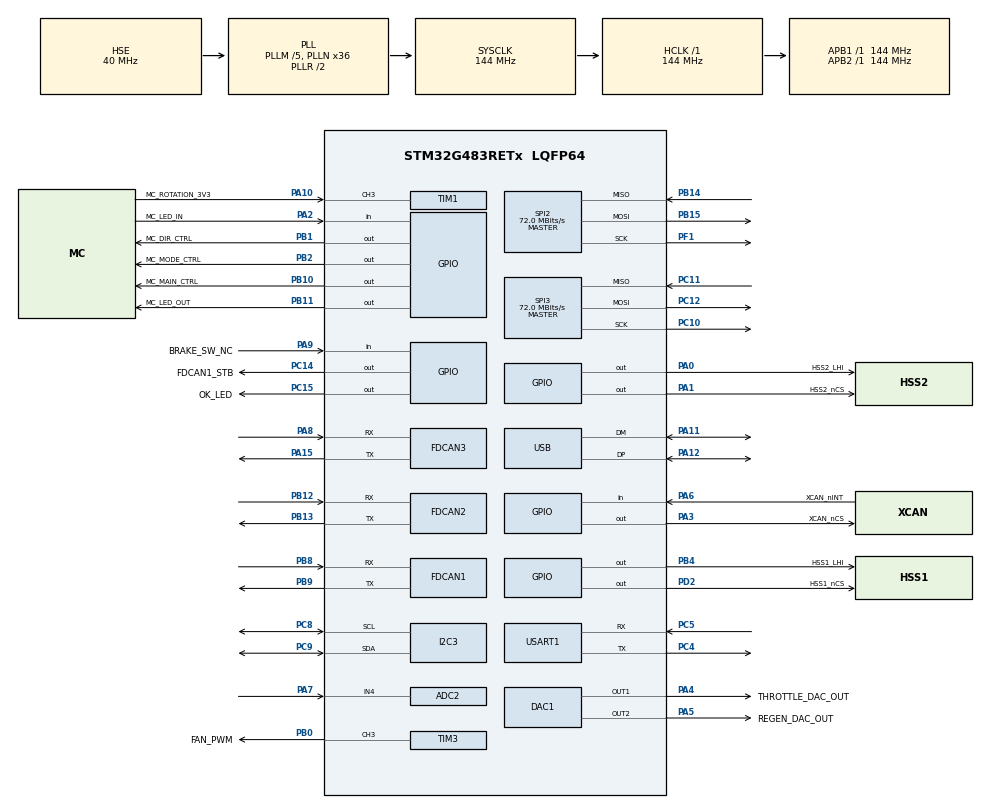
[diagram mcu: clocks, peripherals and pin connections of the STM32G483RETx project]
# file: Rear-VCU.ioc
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ADC2.Channel-0\#ChannelRegularConversion=ADC_CHANNEL_4
ADC2.NbrOfConversionFlag=1
ADC2.OffsetNumber-0\#ChannelRegularConversion=ADC_OFFSET_NONE
ADC2.Rank-0\#ChannelRegularConversion=1
ADC2.SamplingTime-0\#ChannelRegularConversion=ADC_SAMPLETIME_2CYCLES_5
DAC1.DAC_Channel-DAC_OUT2=DAC_CHANNEL_2
FDCAN1.CalculateBaudRateNominal=2999999
FDCAN1.CalculateTimeBitNominal=333
FDCAN1.CalculateTimeQuantumNominal=111.11111111111111
FDCAN2.CalculateBaudRateNominal=2999999
FDCAN2.CalculateTimeBitNominal=333
FDCAN2.CalculateTimeQuantumNominal=111.11111111111111
FDCAN3.CalculateBaudRateNominal=2999999
FDCAN3.CalculateTimeBitNominal=333
FDCAN3.CalculateTimeQuantumNominal=111.11111111111111
FREERTOS.Tasks01=defaultTask,24,128,StartDefaultTask,Default,NULL,Dynamic,NULL,NULL
I2C3.Timing=0x60715075
Mcu.Family=STM32G4
Mcu.Name=STM32G483RETx
Mcu.Package=LQFP64
NVIC.PriorityGroup=NVIC_PRIORITYGROUP_4
NVIC.USB_LP_IRQn=true\:5\:0\:false\:false\:true\:true\:false\:true\:true
PA0.GPIO_Label=HSS2_LHI
PA0.Signal=GPIO_Output
PA1.GPIO_Label=HSS2_nCS
PA1.Signal=GPIO_Output
PA10.GPIO_Label=MC_ROTATION_3V3
PA10.Signal=S_TIM1_CH3
PA11.Mode=Device
PA11.Signal=USB_DM
PA12.Mode=Device
PA12.Signal=USB_DP
PA13.Mode=Trace_Asynchronous_SW
PA13.Signal=SYS_JTMS-SWDIO
PA14.Mode=Trace_Asynchronous_SW
PA14.Signal=SYS_JTCK-SWCLK
PA15.Mode=FDCAN_Activate
PA15.Signal=FDCAN3_TX
PA2.GPIO_Label=MC_LED_IN
PA2.Signal=GPIO_Input
PA3.GPIO_Label=XCAN_nCS
PA3.Signal=GPIO_Output
PA4.GPIO_Label=THROTTLE_DAC_OUT
PA4.Signal=COMP_DAC11_group
PA5.GPIO_Label=REGEN_DAC_OUT
PA5.Signal=COMP_DAC12_group
PA6.GPIO_Label=XCAN_nINT
PA6.Signal=GPIO_Input
PA7.Mode=IN4-Single-Ended
PA7.Signal=ADC2_IN4
PA8.Mode=FDCAN_Activate
PA8.Signal=FDCAN3_RX
PA9.GPIO_Label=BRAKE_SW_NC
PA9.Signal=GPIO_Input
PB0.GPIO_Label=FAN_PWM
PB0.Signal=S_TIM3_CH3
PB1.GPIO_Label=MC_DIR_CTRL
PB1.Signal=GPIO_Output
PB10.GPIO_Label=MC_MAIN_CTRL
PB10.Signal=GPIO_Output
PB11.GPIO_Label=MC_LED_OUT
PB11.Signal=GPIO_Output
PB12.Mode=FDCAN_Activate
PB12.Signal=FDCAN2_RX
PB13.Mode=FDCAN_Activate
PB13.Signal=FDCAN2_TX
PB14.Mode=Full_Duplex_Master
PB14.Signal=SPI2_MISO
PB15.Mode=Full_Duplex_Master
PB15.Signal=SPI2_MOSI
PB2.GPIO_Label=MC_MODE_CTRL
PB2.Signal=GPIO_Output
PB3.Mode=Trace_Asynchronous_SW
PB3.Signal=SYS_JTDO-SWO
PB4.GPIO_Label=HSS1_LHI
PB4.Signal=GPIO_Output
PB8-BOOT0.Mode=FDCAN_Activate
PB8-BOOT0.Signal=FDCAN1_RX
PB9.Mode=FDCAN_Activate
PB9.Signal=FDCAN1_TX
PC10.Mode=Full_Duplex_Master
PC10.Signal=SPI3_SCK
PC11.Mode=Full_Duplex_Master
PC11.Signal=SPI3_MISO
PC12.Mode=Full_Duplex_Master
PC12.Signal=SPI3_MOSI
PC14-OSC32_IN.GPIO_Label=FDCAN1_STB
PC14-OSC32_IN.Signal=GPIO_Output
PC15-OSC32_OUT.GPIO_Label=OK_LED
PC15-OSC32_OUT.Signal=GPIO_Output
PC4.Mode=Asynchronous
PC4.Signal=USART1_TX
PC5.Mode=Asynchronous
PC5.Signal=USART1_RX
PC8.Mode=I2C
PC8.Signal=I2C3_SCL
PC9.Mode=I2C
PC9.Signal=I2C3_SDA
PD2.GPIO_Label=HSS1_nCS
PD2.Signal=GPIO_Output
PF0-OSC_IN.Mode=HSE-External-Clock-Source
PF0-OSC_IN.Signal=RCC_OSC_IN
PF1-OSC_OUT.Mode=Full_Duplex_Master
PF1-OSC_OUT.Signal=SPI2_SCK
ProjectManager.HeapSize=0x200
ProjectManager.StackSize=0x400
ProjectManager.TargetToolchain=Makefile
RCC.ADC12Freq_Value=144000000
RCC.ADC345Freq_Value=144000000
RCC.AHBFreq_Value=144000000
RCC.APB1Freq_Value=144000000
RCC.APB1TimFreq_Value=144000000
RCC.APB2Freq_Value=144000000
RCC.APB2TimFreq_Value=144000000
RCC.CortexFreq_Value=144000000
RCC.EXTERNAL_CLOCK_VALUE=12288000
RCC.EnbaleCSS=true
RCC.HCLKFreq_Value=144000000
RCC.HSE_VALUE=40000000
RCC.HSI48_VALUE=48000000
RCC.HSI_VALUE=16000000
RCC.LSE_VALUE=32768
RCC.PLLM=RCC_PLLM_DIV5
RCC.PLLN=36
RCC.PLLQ=RCC_PLLQ_DIV6
RCC.PLLSourceVirtual=RCC_PLLSOURCE_HSE
RCC.SYSCLKFreq_VALUE=144000000
RCC.SYSCLKSource=RCC_SYSCLKSOURCE_PLLCLK
RCC.USBFreq_Value=48000000
RCC.VCOOutputFreq_Value=288000000
SH.COMP_DAC11_group.0=DAC1_OUT1,DAC_OUT1
SH.COMP_DAC12_group.0=DAC1_OUT2,DAC_OUT2
SH.S_TIM1_CH3.0=TIM1_CH3,Input_Capture3_from_TI3
SH.S_TIM3_CH3.0=TIM3_CH3,PWM Generation3 CH3
SPI2.CalculateBaudRate=72.0 MBits/s
SPI2.Direction=SPI_DIRECTION_2LINES
SPI2.Mode=SPI_MODE_MASTER
SPI2.VirtualType=VM_MASTER
SPI3.CalculateBaudRate=72.0 MBits/s
SPI3.Direction=SPI_DIRECTION_2LINES
SPI3.Mode=SPI_MODE_MASTER
SPI3.VirtualType=VM_MASTER
SYS.VoltageScaling=SYSCFG_VREFBUF_VOLTAGE_SCALE1
TIM1.Channel-Input_Capture3_from_TI3=TIM_CHANNEL_3
TIM3.Channel-PWM\ Generation3\ CH3=TIM_CHANNEL_3
USART1.VirtualMode-Asynchronous=VM_ASYNC
USB_DEVICE.CLASS_NAME_FS=CDC
USB_DEVICE.USBD_SELF_POWERED=0
USB_DEVICE.VirtualMode=Cdc
USB_DEVICE.VirtualModeFS=Cdc_FS
VP_FREERTOS_VS_CMSIS_V2.Mode=CMSIS_V2
VP_SYS_VS_DBSignals.Mode=DisableDeadBatterySignals
VP_USB_DEVICE_VS_USB_DEVICE_CDC_FS.Mode=CDC_FS
VREF+.Mode=InternalMode
VREF+.Signal=VREFBUF_OUT
board=custom

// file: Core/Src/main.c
/* USER CODE BEGIN Header */
/**
  ******************************************************************************
  * @file           : main.c
  * @brief          : Main program body
  ******************************************************************************
  * @attention
  *
  * Copyright (c) 2026 STMicroelectronics.
  * All rights reserved.
  *
  * This software is licensed under terms that can be found in the LICENSE file
  * in the root directory of this software component.
  * If no LICENSE file comes with this software, it is provided AS-IS.
  *
  ******************************************************************************
  */
/* USER CODE END Header */
#include "main.h"
#include "cmsis_os.h"
#include "usb_device.h"

/* USER CODE BEGIN Includes */
#include "user_threads.h"
/* USER CODE END Includes */

ADC_HandleTypeDef hadc2;

DAC_HandleTypeDef hdac1;

FDCAN_HandleTypeDef hfdcan1;
FDCAN_HandleTypeDef hfdcan2;
FDCAN_HandleTypeDef hfdcan3;

I2C_HandleTypeDef hi2c3;

SPI_HandleTypeDef hspi2;
SPI_HandleTypeDef hspi3;

TIM_HandleTypeDef htim1;
TIM_HandleTypeDef htim3;

UART_HandleTypeDef huart1;

/* Definitions for defaultTask */
osThreadId_t defaultTaskHandle;
const osThreadAttr_t defaultTask_attributes = {
  .name = "defaultTask",
  .priority = (osPriority_t) osPriorityNormal,
  .stack_size = 128 * 4
};

void SystemClock_Config(void);
static void MX_GPIO_Init(void);
static void MX_FDCAN1_Init(void);
static void MX_FDCAN2_Init(void);
static void MX_FDCAN3_Init(void);
static void MX_DAC1_Init(void);
static void MX_I2C3_Init(void);
static void MX_SPI2_Init(void);
static void MX_SPI3_Init(void);
static void MX_TIM1_Init(void);
static void MX_TIM3_Init(void);
static void MX_USART1_UART_Init(void);
static void MX_ADC2_Init(void);
void StartDefaultTask(void *argument);

int main(void)
{

  /* MCU Configuration--------------------------------------------------------*/

  /* Reset of all peripherals, Initializes the Flash interface and the Systick. */
  HAL_Init();

  /* Configure the system clock */
  SystemClock_Config();

  /* Initialize all configured peripherals */
  MX_GPIO_Init();
  MX_FDCAN1_Init();
  MX_FDCAN2_Init();
  MX_FDCAN3_Init();
  MX_DAC1_Init();
  MX_I2C3_Init();
  MX_SPI2_Init();
  MX_SPI3_Init();
  MX_TIM1_Init();
  MX_TIM3_Init();
  MX_USART1_UART_Init();
  MX_ADC2_Init();

  /* Init scheduler */
  osKernelInitialize();

  /* Create the thread(s) */
  /* creation of defaultTask */
  defaultTaskHandle = osThreadNew(StartDefaultTask, NULL, &defaultTask_attributes);

  /* Start scheduler */
  osKernelStart();

  /* We should never get here as control is now taken by the scheduler */

  /* Infinite loop */
  while (1)
  {

  }
}

void SystemClock_Config(void)
{
  RCC_OscInitTypeDef RCC_OscInitStruct = {0};
  RCC_ClkInitTypeDef RCC_ClkInitStruct = {0};

  /** Configure the main internal regulator output voltage
  */
  HAL_PWREx_ControlVoltageScaling(PWR_REGULATOR_VOLTAGE_SCALE1);

  /** Initializes the RCC Oscillators according to the specified parameters
  * in the RCC_OscInitTypeDef structure.
  */
  RCC_OscInitStruct.OscillatorType = RCC_OSCILLATORTYPE_HSE;
  RCC_OscInitStruct.HSEState = RCC_HSE_BYPASS;
  RCC_OscInitStruct.PLL.PLLState = RCC_PLL_ON;
  RCC_OscInitStruct.PLL.PLLSource = RCC_PLLSOURCE_HSE;
  RCC_OscInitStruct.PLL.PLLM = RCC_PLLM_DIV5;
  RCC_OscInitStruct.PLL.PLLN = 36;
  RCC_OscInitStruct.PLL.PLLP = RCC_PLLP_DIV2;
  RCC_OscInitStruct.PLL.PLLQ = RCC_PLLQ_DIV6;
  RCC_OscInitStruct.PLL.PLLR = RCC_PLLR_DIV2;
  if (HAL_RCC_OscConfig(&RCC_OscInitStruct) != HAL_OK)
  {
    Error_Handler();
  }

  /** Initializes the CPU, AHB and APB buses clocks
  */
  RCC_ClkInitStruct.ClockType = RCC_CLOCKTYPE_HCLK|RCC_CLOCKTYPE_SYSCLK
                              |RCC_CLOCKTYPE_PCLK1|RCC_CLOCKTYPE_PCLK2;
  RCC_ClkInitStruct.SYSCLKSource = RCC_SYSCLKSOURCE_PLLCLK;
  RCC_ClkInitStruct.AHBCLKDivider = RCC_SYSCLK_DIV1;
  RCC_ClkInitStruct.APB1CLKDivider = RCC_HCLK_DIV1;
  RCC_ClkInitStruct.APB2CLKDivider = RCC_HCLK_DIV1;

  if (HAL_RCC_ClockConfig(&RCC_ClkInitStruct, FLASH_LATENCY_4) != HAL_OK)
  {
    Error_Handler();
  }

  /** Enables the Clock Security System
  */
  HAL_RCC_EnableCSS();
}

static void MX_ADC2_Init(void)
{

  ADC_ChannelConfTypeDef sConfig = {0};

  /** Common config
  */
  hadc2.Instance = ADC2;
  hadc2.Init.ClockPrescaler = ADC_CLOCK_SYNC_PCLK_DIV4;
  hadc2.Init.Resolution = ADC_RESOLUTION_12B;
  hadc2.Init.DataAlign = ADC_DATAALIGN_RIGHT;
  hadc2.Init.GainCompensation = 0;
  hadc2.Init.ScanConvMode = ADC_SCAN_DISABLE;
  hadc2.Init.EOCSelection = ADC_EOC_SINGLE_CONV;
  hadc2.Init.LowPowerAutoWait = DISABLE;
  hadc2.Init.ContinuousConvMode = DISABLE;
  hadc2.Init.NbrOfConversion = 1;
  hadc2.Init.DiscontinuousConvMode = DISABLE;
  hadc2.Init.ExternalTrigConv = ADC_SOFTWARE_START;
  hadc2.Init.ExternalTrigConvEdge = ADC_EXTERNALTRIGCONVEDGE_NONE;
  hadc2.Init.DMAContinuousRequests = DISABLE;
  hadc2.Init.Overrun = ADC_OVR_DATA_PRESERVED;
  hadc2.Init.OversamplingMode = DISABLE;
  if (HAL_ADC_Init(&hadc2) != HAL_OK)
  {
    Error_Handler();
  }

  /** Configure Regular Channel
  */
  sConfig.Channel = ADC_CHANNEL_4;
  sConfig.Rank = ADC_REGULAR_RANK_1;
  sConfig.SamplingTime = ADC_SAMPLETIME_2CYCLES_5;
  sConfig.SingleDiff = ADC_SINGLE_ENDED;
  sConfig.OffsetNumber = ADC_OFFSET_NONE;
  sConfig.Offset = 0;
  if (HAL_ADC_ConfigChannel(&hadc2, &sConfig) != HAL_OK)
  {
    Error_Handler();
  }

}

static void MX_DAC1_Init(void)
{

  DAC_ChannelConfTypeDef sConfig = {0};

  /** DAC Initialization
  */
  hdac1.Instance = DAC1;
  if (HAL_DAC_Init(&hdac1) != HAL_OK)
  {
    Error_Handler();
  }

  /** DAC channel OUT1 config
  */
  sConfig.DAC_HighFrequency = DAC_HIGH_FREQUENCY_INTERFACE_MODE_AUTOMATIC;
  sConfig.DAC_DMADoubleDataMode = DISABLE;
  sConfig.DAC_SignedFormat = DISABLE;
  sConfig.DAC_SampleAndHold = DAC_SAMPLEANDHOLD_DISABLE;
  sConfig.DAC_Trigger = DAC_TRIGGER_NONE;
  sConfig.DAC_Trigger2 = DAC_TRIGGER_NONE;
  sConfig.DAC_OutputBuffer = DAC_OUTPUTBUFFER_ENABLE;
  sConfig.DAC_ConnectOnChipPeripheral = DAC_CHIPCONNECT_EXTERNAL;
  sConfig.DAC_UserTrimming = DAC_TRIMMING_FACTORY;
  if (HAL_DAC_ConfigChannel(&hdac1, &sConfig, DAC_CHANNEL_1) != HAL_OK)
  {
    Error_Handler();
  }

  /** DAC channel OUT2 config
  */
  if (HAL_DAC_ConfigChannel(&hdac1, &sConfig, DAC_CHANNEL_2) != HAL_OK)
  {
    Error_Handler();
  }

}

static void MX_FDCAN1_Init(void)
{

  hfdcan1.Instance = FDCAN1;
  hfdcan1.Init.ClockDivider = FDCAN_CLOCK_DIV1;
  hfdcan1.Init.FrameFormat = FDCAN_FRAME_CLASSIC;
  hfdcan1.Init.Mode = FDCAN_MODE_NORMAL;
  hfdcan1.Init.AutoRetransmission = DISABLE;
  hfdcan1.Init.TransmitPause = DISABLE;
  hfdcan1.Init.ProtocolException = DISABLE;
  hfdcan1.Init.NominalPrescaler = 16;
  hfdcan1.Init.NominalSyncJumpWidth = 1;
  hfdcan1.Init.NominalTimeSeg1 = 1;
  hfdcan1.Init.NominalTimeSeg2 = 1;
  hfdcan1.Init.DataPrescaler = 1;
  hfdcan1.Init.DataSyncJumpWidth = 1;
  hfdcan1.Init.DataTimeSeg1 = 1;
  hfdcan1.Init.DataTimeSeg2 = 1;
  hfdcan1.Init.StdFiltersNbr = 0;
  hfdcan1.Init.ExtFiltersNbr = 0;
  hfdcan1.Init.TxFifoQueueMode = FDCAN_TX_FIFO_OPERATION;
  if (HAL_FDCAN_Init(&hfdcan1) != HAL_OK)
  {
    Error_Handler();
  }

}

static void MX_FDCAN2_Init(void)
{

  hfdcan2.Instance = FDCAN2;
  hfdcan2.Init.ClockDivider = FDCAN_CLOCK_DIV1;
  hfdcan2.Init.FrameFormat = FDCAN_FRAME_CLASSIC;
  hfdcan2.Init.Mode = FDCAN_MODE_NORMAL;
  hfdcan2.Init.AutoRetransmission = DISABLE;
  hfdcan2.Init.TransmitPause = DISABLE;
  hfdcan2.Init.ProtocolException = DISABLE;
  hfdcan2.Init.NominalPrescaler = 16;
  hfdcan2.Init.NominalSyncJumpWidth = 1;
  hfdcan2.Init.NominalTimeSeg1 = 1;
  hfdcan2.Init.NominalTimeSeg2 = 1;
  hfdcan2.Init.DataPrescaler = 1;
  hfdcan2.Init.DataSyncJumpWidth = 1;
  hfdcan2.Init.DataTimeSeg1 = 1;
  hfdcan2.Init.DataTimeSeg2 = 1;
  hfdcan2.Init.StdFiltersNbr = 0;
  hfdcan2.Init.ExtFiltersNbr = 0;
  hfdcan2.Init.TxFifoQueueMode = FDCAN_TX_FIFO_OPERATION;
  if (HAL_FDCAN_Init(&hfdcan2) != HAL_OK)
  {
    Error_Handler();
  }

}

static void MX_FDCAN3_Init(void)
{

  hfdcan3.Instance = FDCAN3;
  hfdcan3.Init.ClockDivider = FDCAN_CLOCK_DIV1;
  hfdcan3.Init.FrameFormat = FDCAN_FRAME_CLASSIC;
  hfdcan3.Init.Mode = FDCAN_MODE_NORMAL;
  hfdcan3.Init.AutoRetransmission = DISABLE;
  hfdcan3.Init.TransmitPause = DISABLE;
  hfdcan3.Init.ProtocolException = DISABLE;
  hfdcan3.Init.NominalPrescaler = 16;
  hfdcan3.Init.NominalSyncJumpWidth = 1;
  hfdcan3.Init.NominalTimeSeg1 = 1;
  hfdcan3.Init.NominalTimeSeg2 = 1;
  hfdcan3.Init.DataPrescaler = 1;
  hfdcan3.Init.DataSyncJumpWidth = 1;
  hfdcan3.Init.DataTimeSeg1 = 1;
  hfdcan3.Init.DataTimeSeg2 = 1;
  hfdcan3.Init.StdFiltersNbr = 0;
  hfdcan3.Init.ExtFiltersNbr = 0;
  hfdcan3.Init.TxFifoQueueMode = FDCAN_TX_FIFO_OPERATION;
  if (HAL_FDCAN_Init(&hfdcan3) != HAL_OK)
  {
    Error_Handler();
  }

}

static void MX_I2C3_Init(void)
{

  hi2c3.Instance = I2C3;
  hi2c3.Init.Timing = 0x60715075;
  hi2c3.Init.OwnAddress1 = 0;
  hi2c3.Init.AddressingMode = I2C_ADDRESSINGMODE_7BIT;
  hi2c3.Init.DualAddressMode = I2C_DUALADDRESS_DISABLE;
  hi2c3.Init.OwnAddress2 = 0;
  hi2c3.Init.OwnAddress2Masks = I2C_OA2_NOMASK;
  hi2c3.Init.GeneralCallMode = I2C_GENERALCALL_DISABLE;
  hi2c3.Init.NoStretchMode = I2C_NOSTRETCH_DISABLE;
  if (HAL_I2C_Init(&hi2c3) != HAL_OK)
  {
    Error_Handler();
  }

  /** Configure Analogue filter
  */
  if (HAL_I2CEx_ConfigAnalogFilter(&hi2c3, I2C_ANALOGFILTER_ENABLE) != HAL_OK)
  {
    Error_Handler();
  }

  /** Configure Digital filter
  */
  if (HAL_I2CEx_ConfigDigitalFilter(&hi2c3, 0) != HAL_OK)
  {
    Error_Handler();
  }

}

static void MX_SPI2_Init(void)
{

  /* SPI2 parameter configuration*/
  hspi2.Instance = SPI2;
  hspi2.Init.Mode = SPI_MODE_MASTER;
  hspi2.Init.Direction = SPI_DIRECTION_2LINES;
  hspi2.Init.DataSize = SPI_DATASIZE_4BIT;
  hspi2.Init.CLKPolarity = SPI_POLARITY_LOW;
  hspi2.Init.CLKPhase = SPI_PHASE_1EDGE;
  hspi2.Init.NSS = SPI_NSS_SOFT;
  hspi2.Init.BaudRatePrescaler = SPI_BAUDRATEPRESCALER_2;
  hspi2.Init.FirstBit = SPI_FIRSTBIT_MSB;
  hspi2.Init.TIMode = SPI_TIMODE_DISABLE;
  hspi2.Init.CRCCalculation = SPI_CRCCALCULATION_DISABLE;
  hspi2.Init.CRCPolynomial = 7;
  hspi2.Init.CRCLength = SPI_CRC_LENGTH_DATASIZE;
  hspi2.Init.NSSPMode = SPI_NSS_PULSE_ENABLE;
  if (HAL_SPI_Init(&hspi2) != HAL_OK)
  {
    Error_Handler();
  }

}

static void MX_SPI3_Init(void)
{

  /* SPI3 parameter configuration*/
  hspi3.Instance = SPI3;
  hspi3.Init.Mode = SPI_MODE_MASTER;
  hspi3.Init.Direction = SPI_DIRECTION_2LINES;
  hspi3.Init.DataSize = SPI_DATASIZE_4BIT;
  hspi3.Init.CLKPolarity = SPI_POLARITY_LOW;
  hspi3.Init.CLKPhase = SPI_PHASE_1EDGE;
  hspi3.Init.NSS = SPI_NSS_SOFT;
  hspi3.Init.BaudRatePrescaler = SPI_BAUDRATEPRESCALER_2;
  hspi3.Init.FirstBit = SPI_FIRSTBIT_MSB;
  hspi3.Init.TIMode = SPI_TIMODE_DISABLE;
  hspi3.Init.CRCCalculation = SPI_CRCCALCULATION_DISABLE;
  hspi3.Init.CRCPolynomial = 7;
  hspi3.Init.CRCLength = SPI_CRC_LENGTH_DATASIZE;
  hspi3.Init.NSSPMode = SPI_NSS_PULSE_ENABLE;
  if (HAL_SPI_Init(&hspi3) != HAL_OK)
  {
    Error_Handler();
  }

}

static void MX_TIM1_Init(void)
{

  TIM_MasterConfigTypeDef sMasterConfig = {0};
  TIM_IC_InitTypeDef sConfigIC = {0};

  htim1.Instance = TIM1;
  htim1.Init.Prescaler = 0;
  htim1.Init.CounterMode = TIM_COUNTERMODE_UP;
  htim1.Init.Period = 65535;
  htim1.Init.ClockDivision = TIM_CLOCKDIVISION_DIV1;
  htim1.Init.RepetitionCounter = 0;
  htim1.Init.AutoReloadPreload = TIM_AUTORELOAD_PRELOAD_DISABLE;
  if (HAL_TIM_IC_Init(&htim1) != HAL_OK)
  {
    Error_Handler();
  }
  sMasterConfig.MasterOutputTrigger = TIM_TRGO_RESET;
  sMasterConfig.MasterOutputTrigger2 = TIM_TRGO2_RESET;
  sMasterConfig.MasterSlaveMode = TIM_MASTERSLAVEMODE_DISABLE;
  if (HAL_TIMEx_MasterConfigSynchronization(&htim1, &sMasterConfig) != HAL_OK)
  {
    Error_Handler();
  }
  sConfigIC.ICPolarity = TIM_INPUTCHANNELPOLARITY_RISING;
  sConfigIC.ICSelection = TIM_ICSELECTION_DIRECTTI;
  sConfigIC.ICPrescaler = TIM_ICPSC_DIV1;
  sConfigIC.ICFilter = 0;
  if (HAL_TIM_IC_ConfigChannel(&htim1, &sConfigIC, TIM_CHANNEL_3) != HAL_OK)
  {
    Error_Handler();
  }

}

static void MX_TIM3_Init(void)
{

  TIM_MasterConfigTypeDef sMasterConfig = {0};
  TIM_OC_InitTypeDef sConfigOC = {0};

  htim3.Instance = TIM3;
  htim3.Init.Prescaler = 0;
  htim3.Init.CounterMode = TIM_COUNTERMODE_UP;
  htim3.Init.Period = 65535;
  htim3.Init.ClockDivision = TIM_CLOCKDIVISION_DIV1;
  htim3.Init.AutoReloadPreload = TIM_AUTORELOAD_PRELOAD_DISABLE;
  if (HAL_TIM_PWM_Init(&htim3) != HAL_OK)
  {
    Error_Handler();
  }
  sMasterConfig.MasterOutputTrigger = TIM_TRGO_RESET;
  sMasterConfig.MasterSlaveMode = TIM_MASTERSLAVEMODE_DISABLE;
  if (HAL_TIMEx_MasterConfigSynchronization(&htim3, &sMasterConfig) != HAL_OK)
  {
    Error_Handler();
  }
  sConfigOC.OCMode = TIM_OCMODE_PWM1;
  sConfigOC.Pulse = 0;
  sConfigOC.OCPolarity = TIM_OCPOLARITY_HIGH;
  sConfigOC.OCFastMode = TIM_OCFAST_DISABLE;
  if (HAL_TIM_PWM_ConfigChannel(&htim3, &sConfigOC, TIM_CHANNEL_3) != HAL_OK)
  {
    Error_Handler();
  }
  HAL_TIM_MspPostInit(&htim3);

}

static void MX_USART1_UART_Init(void)
{

  huart1.Instance = USART1;
  huart1.Init.BaudRate = 115200;
  huart1.Init.WordLength = UART_WORDLENGTH_8B;
  huart1.Init.StopBits = UART_STOPBITS_1;
  huart1.Init.Parity = UART_PARITY_NONE;
  huart1.Init.Mode = UART_MODE_TX_RX;
  huart1.Init.HwFlowCtl = UART_HWCONTROL_NONE;
  huart1.Init.OverSampling = UART_OVERSAMPLING_16;
  huart1.Init.OneBitSampling = UART_ONE_BIT_SAMPLE_DISABLE;
  huart1.Init.ClockPrescaler = UART_PRESCALER_DIV1;
  huart1.AdvancedInit.AdvFeatureInit = UART_ADVFEATURE_NO_INIT;
  if (HAL_UART_Init(&huart1) != HAL_OK)
  {
    Error_Handler();
  }
  if (HAL_UARTEx_SetTxFifoThreshold(&huart1, UART_TXFIFO_THRESHOLD_1_8) != HAL_OK)
  {
    Error_Handler();
  }
  if (HAL_UARTEx_SetRxFifoThreshold(&huart1, UART_RXFIFO_THRESHOLD_1_8) != HAL_OK)
  {
    Error_Handler();
  }
  if (HAL_UARTEx_DisableFifoMode(&huart1) != HAL_OK)
  {
    Error_Handler();
  }

}

static void MX_GPIO_Init(void)
{
  GPIO_InitTypeDef GPIO_InitStruct = {0};

  /* GPIO Ports Clock Enable */
  __HAL_RCC_GPIOC_CLK_ENABLE();
  __HAL_RCC_GPIOF_CLK_ENABLE();
  __HAL_RCC_GPIOA_CLK_ENABLE();
  __HAL_RCC_GPIOB_CLK_ENABLE();
  __HAL_RCC_GPIOD_CLK_ENABLE();

  /*Configure GPIO pin Output Level */
  HAL_GPIO_WritePin(GPIOC, FDCAN1_STB_Pin|OK_LED_Pin, GPIO_PIN_RESET);

  /*Configure GPIO pin Output Level */
  HAL_GPIO_WritePin(GPIOA, HSS2_LHI_Pin|HSS2_nCS_Pin|XCAN_nCS_Pin, GPIO_PIN_RESET);

  /*Configure GPIO pin Output Level */
  HAL_GPIO_WritePin(GPIOB, MC_DIR_CTRL_Pin|MC_MODE_CTRL_Pin|MC_MAIN_CTRL_Pin|MC_LED_OUT_Pin
                          |HSS1_LHI_Pin, GPIO_PIN_RESET);

  /*Configure GPIO pin Output Level */
  HAL_GPIO_WritePin(HSS1_nCS_GPIO_Port, HSS1_nCS_Pin, GPIO_PIN_RESET);

  /*Configure GPIO pins : FDCAN1_STB_Pin OK_LED_Pin */
  GPIO_InitStruct.Pin = FDCAN1_STB_Pin|OK_LED_Pin;
  GPIO_InitStruct.Mode = GPIO_MODE_OUTPUT_PP;
  GPIO_InitStruct.Pull = GPIO_NOPULL;
  GPIO_InitStruct.Speed = GPIO_SPEED_FREQ_LOW;
  HAL_GPIO_Init(GPIOC, &GPIO_InitStruct);

  /*Configure GPIO pins : HSS2_LHI_Pin HSS2_nCS_Pin XCAN_nCS_Pin */
  GPIO_InitStruct.Pin = HSS2_LHI_Pin|HSS2_nCS_Pin|XCAN_nCS_Pin;
  GPIO_InitStruct.Mode = GPIO_MODE_OUTPUT_PP;
  GPIO_InitStruct.Pull = GPIO_NOPULL;
  GPIO_InitStruct.Speed = GPIO_SPEED_FREQ_LOW;
  HAL_GPIO_Init(GPIOA, &GPIO_InitStruct);

  /*Configure GPIO pins : MC_LED_IN_Pin XCAN_nINT_Pin BRAKE_SW_NC_Pin */
  GPIO_InitStruct.Pin = MC_LED_IN_Pin|XCAN_nINT_Pin|BRAKE_SW_NC_Pin;
  GPIO_InitStruct.Mode = GPIO_MODE_INPUT;
  GPIO_InitStruct.Pull = GPIO_NOPULL;
  HAL_GPIO_Init(GPIOA, &GPIO_InitStruct);

  /*Configure GPIO pins : MC_DIR_CTRL_Pin MC_MODE_CTRL_Pin MC_MAIN_CTRL_Pin MC_LED_OUT_Pin
                           HSS1_LHI_Pin */
  GPIO_InitStruct.Pin = MC_DIR_CTRL_Pin|MC_MODE_CTRL_Pin|MC_MAIN_CTRL_Pin|MC_LED_OUT_Pin
                          |HSS1_LHI_Pin;
  GPIO_InitStruct.Mode = GPIO_MODE_OUTPUT_PP;
  GPIO_InitStruct.Pull = GPIO_NOPULL;
  GPIO_InitStruct.Speed = GPIO_SPEED_FREQ_LOW;
  HAL_GPIO_Init(GPIOB, &GPIO_InitStruct);

  /*Configure GPIO pin : HSS1_nCS_Pin */
  GPIO_InitStruct.Pin = HSS1_nCS_Pin;
  GPIO_InitStruct.Mode = GPIO_MODE_OUTPUT_PP;
  GPIO_InitStruct.Pull = GPIO_NOPULL;
  GPIO_InitStruct.Speed = GPIO_SPEED_FREQ_LOW;
  HAL_GPIO_Init(HSS1_nCS_GPIO_Port, &GPIO_InitStruct);

}

void StartDefaultTask(void *argument)
{
  /* init code for USB_Device */
  MX_USB_Device_Init();
  /* USER CODE BEGIN 5 */
  /* Infinite loop */
  for(;;)
  {
      userDefaultTask(argument);
  }
  /* USER CODE END 5 */
}

void Error_Handler(void)
{
  __disable_irq();
  while (1)
  {
  }
}
